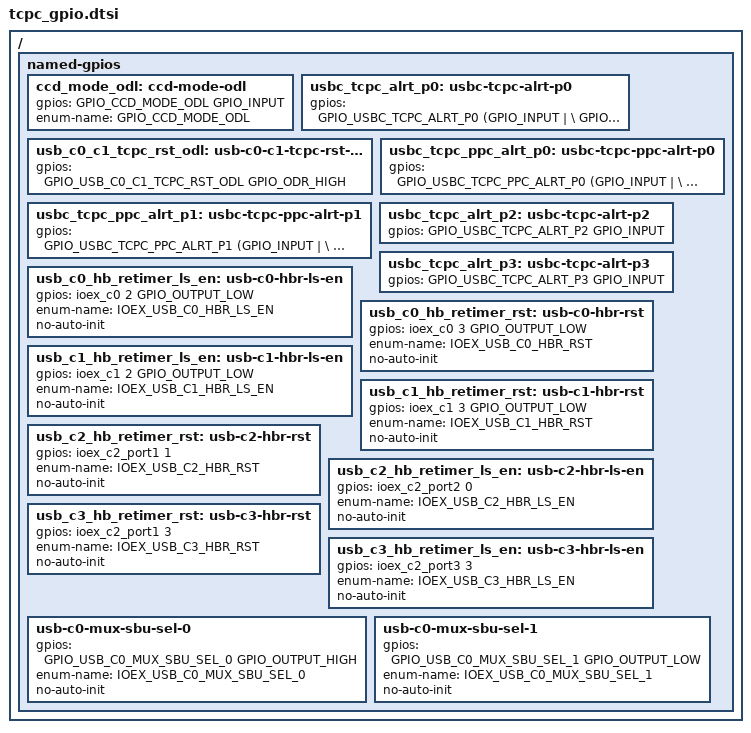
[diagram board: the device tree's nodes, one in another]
/* Copyright 2024 The ChromiumOS Authors
 * Use of this source code is governed by a BSD-style license that can be
 * found in the LICENSE file.
 */

#include <dt-bindings/gpio_defines.h>

/ {
	named-gpios {
		/* NOTE: Netname is USBC_TCPC_ALRT_P3 */
		ccd_mode_odl: ccd-mode-odl {
			gpios = <GPIO_CCD_MODE_ODL GPIO_INPUT>;
			enum-name = "GPIO_CCD_MODE_ODL";
		}; /* GPIO242 */
		usbc_tcpc_alrt_p0: usbc-tcpc-alrt-p0 {
			gpios = <GPIO_USBC_TCPC_ALRT_P0 (GPIO_INPUT | \
				GPIO_ACTIVE_LOW)>;
		}; /* GPIO143 */
		/* NOTE: Netname is USBC_TCPC_PPC_ALRT_P0 */
		usb_c0_c1_tcpc_rst_odl: usb-c0-c1-tcpc-rst-odl {
			gpios = <GPIO_USB_C0_C1_TCPC_RST_ODL GPIO_ODR_HIGH>;
		}; /* GPIO240 */
		/* NOTE: Netname is USBC_TCPC_ALRT_P1 */
		usbc_tcpc_ppc_alrt_p0: usbc-tcpc-ppc-alrt-p0 {
			gpios = <GPIO_USBC_TCPC_PPC_ALRT_P0 (GPIO_INPUT | \
				GPIO_ACTIVE_LOW)>;
		}; /* GPIO241 */
		usbc_tcpc_ppc_alrt_p1: usbc-tcpc-ppc-alrt-p1 {
			gpios = <GPIO_USBC_TCPC_PPC_ALRT_P1 (GPIO_INPUT | \
				GPIO_ACTIVE_LOW)>;
		}; /* GPIO155 */
		usbc_tcpc_alrt_p2: usbc-tcpc-alrt-p2 {
			gpios = <GPIO_USBC_TCPC_ALRT_P2 GPIO_INPUT>;
		}; /* GPIO221 */
		/* NOTE: Netname is USBC_TCPC_PPC_ALRT_P3 */
		usbc_tcpc_alrt_p3: usbc-tcpc-alrt-p3 {
			gpios = <GPIO_USBC_TCPC_ALRT_P3 GPIO_INPUT>;
		}; /* GPIO034 */

		usb_c0_hb_retimer_ls_en: usb-c0-hbr-ls-en {
			gpios = <&ioex_c0 2 GPIO_OUTPUT_LOW>;
			enum-name = "IOEX_USB_C0_HBR_LS_EN";
			no-auto-init;
		};
		usb_c0_hb_retimer_rst: usb-c0-hbr-rst {
			gpios = <&ioex_c0 3 GPIO_OUTPUT_LOW>;
			enum-name = "IOEX_USB_C0_HBR_RST";
			no-auto-init;
		};
		usb_c1_hb_retimer_ls_en: usb-c1-hbr-ls-en {
			gpios = <&ioex_c1 2 GPIO_OUTPUT_LOW>;
			enum-name = "IOEX_USB_C1_HBR_LS_EN";
			no-auto-init;
		};
		usb_c1_hb_retimer_rst: usb-c1-hbr-rst {
			gpios = <&ioex_c1 3 GPIO_OUTPUT_LOW>;
			enum-name = "IOEX_USB_C1_HBR_RST";
			no-auto-init;
		};
		usb_c2_hb_retimer_rst: usb-c2-hbr-rst {
			gpios = <&ioex_c2_port1 1 (GPIO_ODR_LOW | \
				GPIO_VOLTAGE_1P8)>;
			enum-name = "IOEX_USB_C2_HBR_RST";
			no-auto-init;
		};
		usb_c2_hb_retimer_ls_en: usb-c2-hbr-ls-en {
			gpios = <&ioex_c2_port2 0 (GPIO_ODR_LOW | \
				GPIO_VOLTAGE_1P8)>;
			enum-name = "IOEX_USB_C2_HBR_LS_EN";
			no-auto-init;
		};
		usb_c3_hb_retimer_rst: usb-c3-hbr-rst {
			gpios = <&ioex_c2_port1 3 (GPIO_ODR_LOW | \
				GPIO_VOLTAGE_1P8)>;
			enum-name = "IOEX_USB_C3_HBR_RST";
			no-auto-init;
		};
		usb_c3_hb_retimer_ls_en: usb-c3-hbr-ls-en {
			gpios = <&ioex_c2_port3 3 (GPIO_ODR_LOW | \
				GPIO_VOLTAGE_1P8)>;
			enum-name = "IOEX_USB_C3_HBR_LS_EN";
			no-auto-init;
		};
		usb-c0-mux-sbu-sel-0 {
			gpios = <GPIO_USB_C0_MUX_SBU_SEL_0 GPIO_OUTPUT_HIGH>;
			enum-name = "IOEX_USB_C0_MUX_SBU_SEL_0";
			no-auto-init;
		};
		usb-c0-mux-sbu-sel-1 {
			gpios = <GPIO_USB_C0_MUX_SBU_SEL_1 GPIO_OUTPUT_LOW>;
			enum-name = "IOEX_USB_C0_MUX_SBU_SEL_1";
			no-auto-init;
		};
	};
};
